AUTOSAR XML (schema 4-2-2)
package /Components
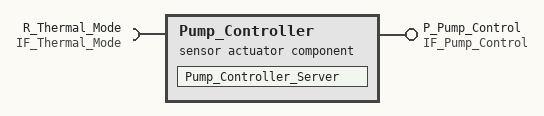
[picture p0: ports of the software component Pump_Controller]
  sensor actuator sw component type Pump_Controller
    provide port P_Pump_Control: provided-interface=IF_Pump_Control
    require port R_Thermal_Mode: required-interface=IF_Thermal_Mode
    behavior Pump_Controller_InternalBehavior
      init event Pump_Controller_Init_Event: start-on-event=Pump_Controller_Server
      operation invoked event Pump_Command_Invoked: start-on-event=Pump_Controller_Server
      runnable Pump_Controller_Server: mode-access-point=R_Thermal_Mode.ThermalModeGroup
        data-receive-point-by-arguments:
          access VA_Arg_target_flow: accessed-variable=P_Pump_Control.target_motor_coolant_flow
          access VA_Arg_pump_temp: accessed-variable=P_Pump_Control.t_pump1_housing
